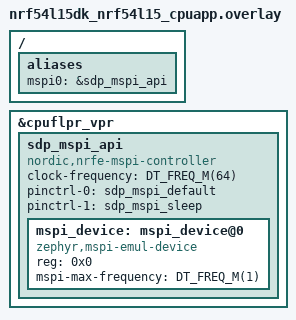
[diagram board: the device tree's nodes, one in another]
/*
 * Copyright (c) 2024 Nordic Semiconductor ASA
 *
 * SPDX-License-Identifier: LicenseRef-Nordic-5-Clause
 */

/ {
	aliases {
		mspi0 = &sdp_mspi_api;
	};
};

&cpuflpr_vpr {
	status = "okay";

	sdp_mspi_api: sdp_mspi_api {
		compatible = "nordic,nrfe-mspi-controller";
		#address-cells = <1>;
		#size-cells = <0>;
		clock-frequency = <DT_FREQ_M(64)>;
		pinctrl-0 = <&sdp_mspi_default>;
		pinctrl-1 = <&sdp_mspi_sleep>;
		pinctrl-names = "default", "sleep";
		status = "okay";

		mspi_device: mspi_device@0 {
			status = "okay";
			compatible = "zephyr,mspi-emul-device";
			reg = <0x0>;
			mspi-max-frequency = <DT_FREQ_M(1)>;
		};
	};
};
